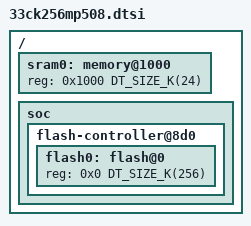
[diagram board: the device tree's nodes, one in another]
/*
 * Copyright (c) 2020 Rubus Technologies Inc.
 *
 * SPDX-License-Identifier: Apache-2.0
 */

#include <mem.h>
#include <dspic33c/33ckxxxmpxxx.dtsi>

/ {
	sram0: memory@1000 {
		reg = <0x1000	DT_SIZE_K(24)>;
	};

	soc {
		flash-controller@8d0 {
			flash0: flash@0 {
				reg = <0x0 DT_SIZE_K(256)>;
			};
		};
	};

};
